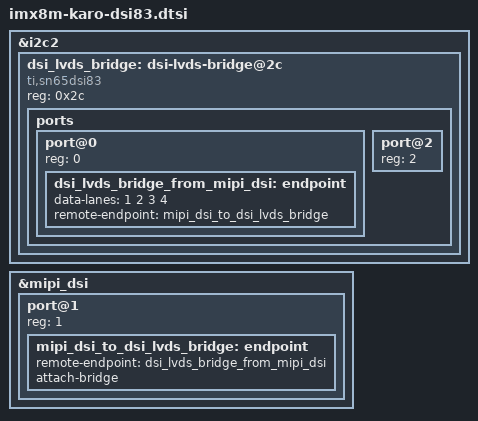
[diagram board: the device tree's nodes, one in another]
// SPDX-License-Identifier: (GPL-2.0 OR MIT)
/*
 * Copyright 2022 Lothar Waßmann <LW@KARO-electronics.de>
 *
 */

&i2c2 {
	dsi_lvds_bridge: dsi-lvds-bridge@2c {
		compatible = "ti,sn65dsi83";
		reg = <0x2c>;
		status = "okay";

		ports {
			port@0 {
				reg = <0>;

				dsi_lvds_bridge_from_mipi_dsi: endpoint {
					data-lanes = <1 2 3 4>;
					remote-endpoint = <&mipi_dsi_to_dsi_lvds_bridge>;
				};

			};

			port@2 {
				reg = <2>;
			};
		};
	};
};

&mipi_dsi {
	status = "okay";

	port@1 {
		reg = <1>;

		mipi_dsi_to_dsi_lvds_bridge: endpoint {
			remote-endpoint = <&dsi_lvds_bridge_from_mipi_dsi>;
			attach-bridge;
		};
	};
};
